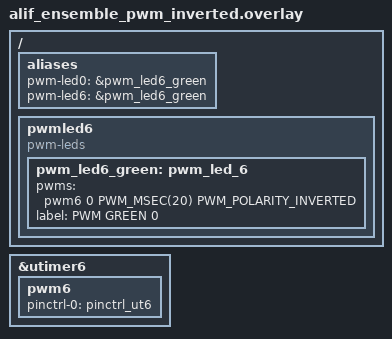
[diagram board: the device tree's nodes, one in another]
/* Copyright Alif Semiconductor - All Rights Reserved.
 * Use, distribution and modification of this code is permitted under the
 * terms stated in the Alif Semiconductor Software License Agreement
 *
 * You should have received a copy of the Alif Semiconductor Software
 * License Agreement with this file. If not, please write to:
 * contact@alifsemi.com, or visit: https://alifsemi.com/license
 */
/ {
		aliases {
				pwm-led0 = &pwm_led6_green;
				pwm-led6 = &pwm_led6_green;
		};
		pwmled6 {
				compatible = "pwm-leds";
				pwm_led6_green: pwm_led_6 {
						pwms = <&pwm6 0 PWM_MSEC(20) PWM_POLARITY_INVERTED>;
						label = "PWM GREEN 0";
				};
		};
};

&utimer6 {
		status = "okay";

		pwm6: pwm6 {
				pinctrl-0 = < &pinctrl_ut6 >;
				pinctrl-names = "default";
				status = "okay";
		};
};
